VERSION "MFE26 real-VC / CarMaker RBS contract"

NS_ :

BS_:

BU_: VC SpeedgoatHIL CarMaker

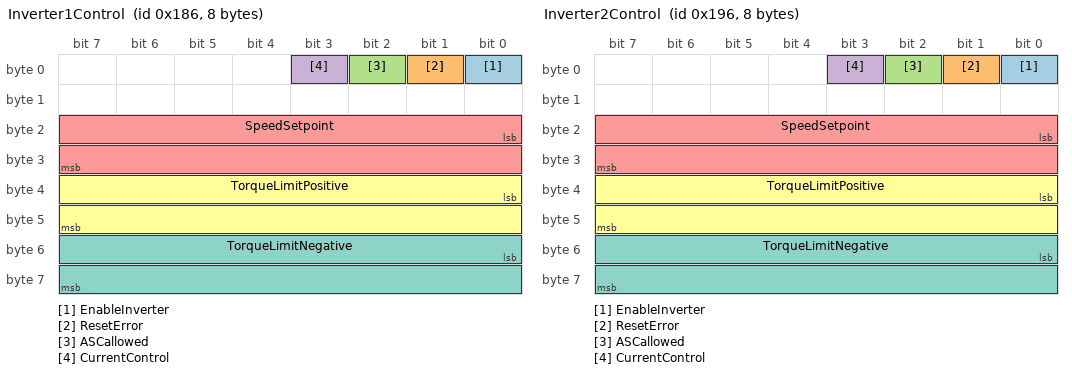
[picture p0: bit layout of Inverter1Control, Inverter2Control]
BO_ 390 Inverter1Control: 8 VC
 SG_ EnableInverter : 0|1@1+ (1,0) [0|1] "" SpeedgoatHIL,CarMaker
 SG_ ResetError : 1|1@1+ (1,0) [0|1] "" SpeedgoatHIL,CarMaker
 SG_ ASCallowed : 2|1@1+ (1,0) [0|1] "" SpeedgoatHIL,CarMaker
 SG_ CurrentControl : 3|1@1+ (1,0) [0|1] "" SpeedgoatHIL,CarMaker
 SG_ SpeedSetpoint : 16|16@1- (1,0) [-32768|32767] "RPM" SpeedgoatHIL,CarMaker
 SG_ TorqueLimitPositive : 32|16@1- (0.00390625,0) [-128|127.99609375] "Nm" SpeedgoatHIL,CarMaker
 SG_ TorqueLimitNegative : 48|16@1- (0.00390625,0) [-128|127.99609375] "Nm" SpeedgoatHIL,CarMaker
BO_ 406 Inverter2Control: 8 VC
 SG_ EnableInverter : 0|1@1+ (1,0) [0|1] "" SpeedgoatHIL,CarMaker
 SG_ ResetError : 1|1@1+ (1,0) [0|1] "" SpeedgoatHIL,CarMaker
 SG_ ASCallowed : 2|1@1+ (1,0) [0|1] "" SpeedgoatHIL,CarMaker
 SG_ CurrentControl : 3|1@1+ (1,0) [0|1] "" SpeedgoatHIL,CarMaker
 SG_ SpeedSetpoint : 16|16@1- (1,0) [-32768|32767] "RPM" SpeedgoatHIL,CarMaker
 SG_ TorqueLimitPositive : 32|16@1- (0.00390625,0) [-128|127.99609375] "Nm" SpeedgoatHIL,CarMaker
 SG_ TorqueLimitNegative : 48|16@1- (0.00390625,0) [-128|127.99609375] "Nm" SpeedgoatHIL,CarMaker
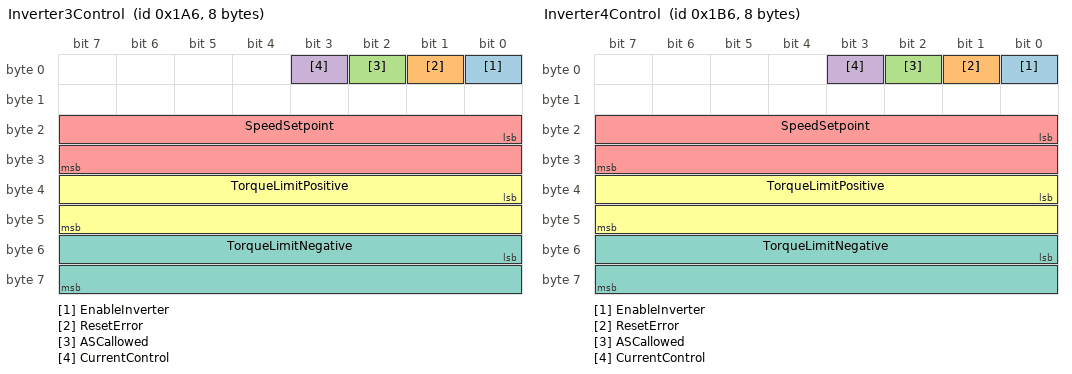
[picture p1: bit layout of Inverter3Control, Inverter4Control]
BO_ 422 Inverter3Control: 8 VC
 SG_ EnableInverter : 0|1@1+ (1,0) [0|1] "" SpeedgoatHIL,CarMaker
 SG_ ResetError : 1|1@1+ (1,0) [0|1] "" SpeedgoatHIL,CarMaker
 SG_ ASCallowed : 2|1@1+ (1,0) [0|1] "" SpeedgoatHIL,CarMaker
 SG_ CurrentControl : 3|1@1+ (1,0) [0|1] "" SpeedgoatHIL,CarMaker
 SG_ SpeedSetpoint : 16|16@1- (1,0) [-32768|32767] "RPM" SpeedgoatHIL,CarMaker
 SG_ TorqueLimitPositive : 32|16@1- (0.00390625,0) [-128|127.99609375] "Nm" SpeedgoatHIL,CarMaker
 SG_ TorqueLimitNegative : 48|16@1- (0.00390625,0) [-128|127.99609375] "Nm" SpeedgoatHIL,CarMaker
BO_ 438 Inverter4Control: 8 VC
 SG_ EnableInverter : 0|1@1+ (1,0) [0|1] "" SpeedgoatHIL,CarMaker
 SG_ ResetError : 1|1@1+ (1,0) [0|1] "" SpeedgoatHIL,CarMaker
 SG_ ASCallowed : 2|1@1+ (1,0) [0|1] "" SpeedgoatHIL,CarMaker
 SG_ CurrentControl : 3|1@1+ (1,0) [0|1] "" SpeedgoatHIL,CarMaker
 SG_ SpeedSetpoint : 16|16@1- (1,0) [-32768|32767] "RPM" SpeedgoatHIL,CarMaker
 SG_ TorqueLimitPositive : 32|16@1- (0.00390625,0) [-128|127.99609375] "Nm" SpeedgoatHIL,CarMaker
 SG_ TorqueLimitNegative : 48|16@1- (0.00390625,0) [-128|127.99609375] "Nm" SpeedgoatHIL,CarMaker

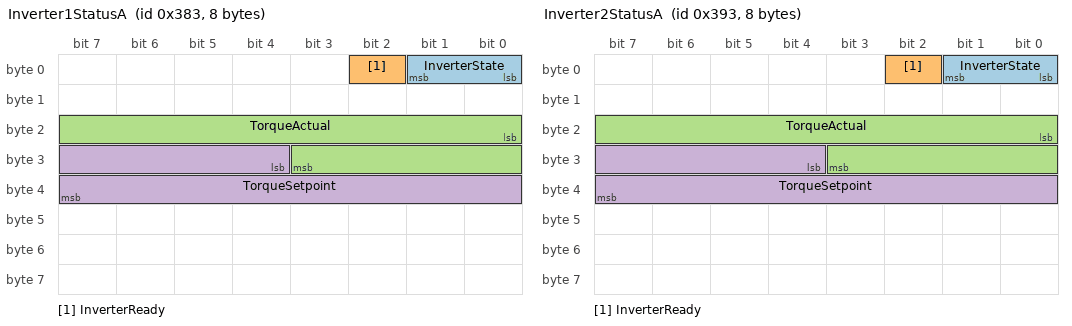
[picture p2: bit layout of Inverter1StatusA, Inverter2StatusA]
BO_ 899 Inverter1StatusA: 8 SpeedgoatHIL
 SG_ InverterState : 0|2@1+ (1,0) [0|3] "" VC,CarMaker
 SG_ InverterReady : 2|1@1+ (1,0) [0|1] "" VC,CarMaker
 SG_ TorqueActual : 16|12@1- (0.03125,0) [-64|63.96875] "Nm" VC,CarMaker
 SG_ TorqueSetpoint : 28|12@1- (0.03125,0) [-64|63.96875] "Nm" VC,CarMaker
BO_ 915 Inverter2StatusA: 8 SpeedgoatHIL
 SG_ InverterState : 0|2@1+ (1,0) [0|3] "" VC,CarMaker
 SG_ InverterReady : 2|1@1+ (1,0) [0|1] "" VC,CarMaker
 SG_ TorqueActual : 16|12@1- (0.03125,0) [-64|63.96875] "Nm" VC,CarMaker
 SG_ TorqueSetpoint : 28|12@1- (0.03125,0) [-64|63.96875] "Nm" VC,CarMaker
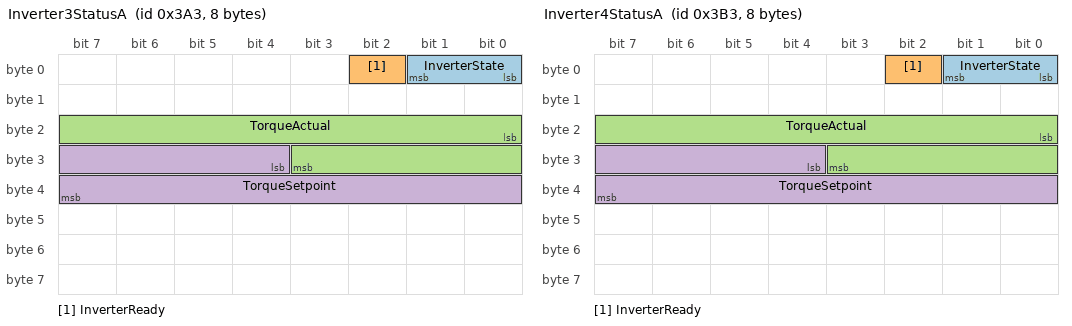
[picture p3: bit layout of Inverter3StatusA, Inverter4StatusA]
BO_ 931 Inverter3StatusA: 8 SpeedgoatHIL
 SG_ InverterState : 0|2@1+ (1,0) [0|3] "" VC,CarMaker
 SG_ InverterReady : 2|1@1+ (1,0) [0|1] "" VC,CarMaker
 SG_ TorqueActual : 16|12@1- (0.03125,0) [-64|63.96875] "Nm" VC,CarMaker
 SG_ TorqueSetpoint : 28|12@1- (0.03125,0) [-64|63.96875] "Nm" VC,CarMaker
BO_ 947 Inverter4StatusA: 8 SpeedgoatHIL
 SG_ InverterState : 0|2@1+ (1,0) [0|3] "" VC,CarMaker
 SG_ InverterReady : 2|1@1+ (1,0) [0|1] "" VC,CarMaker
 SG_ TorqueActual : 16|12@1- (0.03125,0) [-64|63.96875] "Nm" VC,CarMaker
 SG_ TorqueSetpoint : 28|12@1- (0.03125,0) [-64|63.96875] "Nm" VC,CarMaker

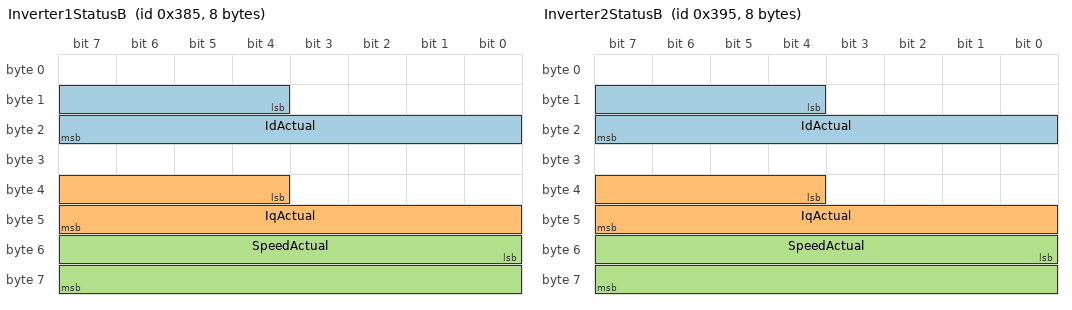
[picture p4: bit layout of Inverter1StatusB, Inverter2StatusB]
BO_ 901 Inverter1StatusB: 8 SpeedgoatHIL
 SG_ IdActual : 12|12@1- (0.0625,0) [-128|127.9375] "Arms" VC,CarMaker
 SG_ IqActual : 36|12@1- (0.0625,0) [-128|127.9375] "Arms" VC,CarMaker
 SG_ SpeedActual : 48|16@1- (1,0) [-32768|32767] "RPM" VC,CarMaker
BO_ 917 Inverter2StatusB: 8 SpeedgoatHIL
 SG_ IdActual : 12|12@1- (0.0625,0) [-128|127.9375] "Arms" VC,CarMaker
 SG_ IqActual : 36|12@1- (0.0625,0) [-128|127.9375] "Arms" VC,CarMaker
 SG_ SpeedActual : 48|16@1- (1,0) [-32768|32767] "RPM" VC,CarMaker
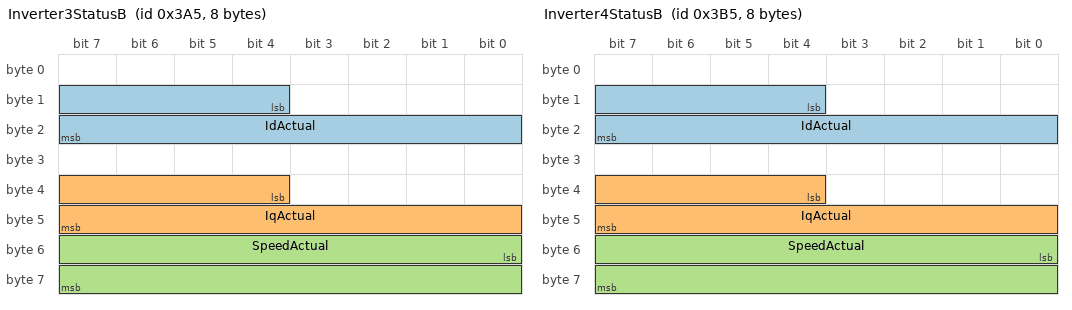
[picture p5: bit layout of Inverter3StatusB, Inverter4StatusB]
BO_ 933 Inverter3StatusB: 8 SpeedgoatHIL
 SG_ IdActual : 12|12@1- (0.0625,0) [-128|127.9375] "Arms" VC,CarMaker
 SG_ IqActual : 36|12@1- (0.0625,0) [-128|127.9375] "Arms" VC,CarMaker
 SG_ SpeedActual : 48|16@1- (1,0) [-32768|32767] "RPM" VC,CarMaker
BO_ 949 Inverter4StatusB: 8 SpeedgoatHIL
 SG_ IdActual : 12|12@1- (0.0625,0) [-128|127.9375] "Arms" VC,CarMaker
 SG_ IqActual : 36|12@1- (0.0625,0) [-128|127.9375] "Arms" VC,CarMaker
 SG_ SpeedActual : 48|16@1- (1,0) [-32768|32767] "RPM" VC,CarMaker
BO_ 1024 DCLinkStatus: 8 SpeedgoatHIL
 SG_ DCLinkVoltage12Actual : 0|16@1+ (0.015625,0) [0|1023.984375] "V" VC,CarMaker
 SG_ DCLinkVoltage34Actual : 16|16@1+ (0.015625,0) [0|1023.984375] "V" VC,CarMaker

BO_ 52 Sensor034: 8 VC
 SG_ RawPayload : 0|64@1+ (1,0) [0|1.8446744073709552e+19] "" SpeedgoatHIL,CarMaker
BO_ 50 Sensor032: 8 VC
 SG_ RawPayload : 0|64@1+ (1,0) [0|1.8446744073709552e+19] "" SpeedgoatHIL,CarMaker
BO_ 688 Sensor2B0: 8 VC
 SG_ RawPayload : 0|64@1+ (1,0) [0|1.8446744073709552e+19] "" SpeedgoatHIL,CarMaker

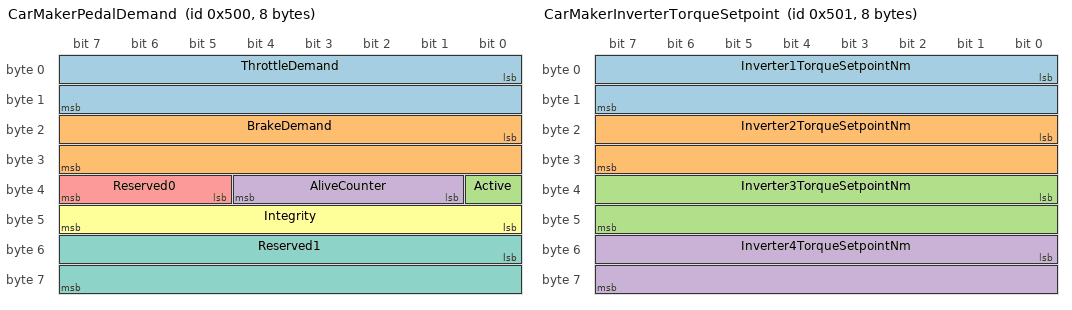
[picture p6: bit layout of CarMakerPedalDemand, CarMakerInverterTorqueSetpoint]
BO_ 1280 CarMakerPedalDemand: 8 CarMaker
 SG_ ThrottleDemand : 0|16@1+ (0.01,0) [0|100] "%" SpeedgoatHIL
 SG_ BrakeDemand : 16|16@1+ (0.01,0) [0|100] "%" SpeedgoatHIL
 SG_ Active : 32|1@1+ (1,0) [0|1] "" SpeedgoatHIL
 SG_ AliveCounter : 33|4@1+ (1,0) [0|15] "" SpeedgoatHIL
 SG_ Reserved0 : 37|3@1+ (1,0) [0|0] "" SpeedgoatHIL
 SG_ Integrity : 40|8@1+ (1,0) [0|255] "" SpeedgoatHIL
 SG_ Reserved1 : 48|16@1+ (1,0) [0|0] "" SpeedgoatHIL

BO_ 1281 CarMakerInverterTorqueSetpoint: 8 SpeedgoatHIL
 SG_ Inverter1TorqueSetpointNm : 0|16@1- (0.03125,0) [-1024|1023.96875] "Nm" CarMaker
 SG_ Inverter2TorqueSetpointNm : 16|16@1- (0.03125,0) [-1024|1023.96875] "Nm" CarMaker
 SG_ Inverter3TorqueSetpointNm : 32|16@1- (0.03125,0) [-1024|1023.96875] "Nm" CarMaker
 SG_ Inverter4TorqueSetpointNm : 48|16@1- (0.03125,0) [-1024|1023.96875] "Nm" CarMaker

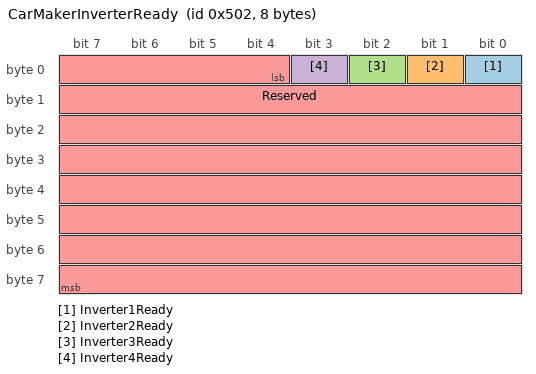
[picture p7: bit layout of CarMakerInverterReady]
BO_ 1282 CarMakerInverterReady: 8 SpeedgoatHIL
 SG_ Inverter1Ready : 0|1@1+ (1,0) [0|1] "" CarMaker
 SG_ Inverter2Ready : 1|1@1+ (1,0) [0|1] "" CarMaker
 SG_ Inverter3Ready : 2|1@1+ (1,0) [0|1] "" CarMaker
 SG_ Inverter4Ready : 3|1@1+ (1,0) [0|1] "" CarMaker
 SG_ Reserved : 4|60@1+ (1,0) [0|0] "" CarMaker

CM_ BO_ 1280 "Proposed design not built. Standard 11-bit ID 0x500, DLC 8, cyclic 10 ms, Intel/little-endian. Authoritative contract: inverter_hil/docs/can_pedal_demand_frame_spec.md on branch SG-CAN. Integrity is CRC-8/SAE-J1850 over bytes 1..5 in transmission order: width 8, poly 0x1D, init 0xFF, RefIn=false, RefOut=false, final XOR 0xFF; check value for five zero bytes is 0x10. Sender increments AliveCounter modulo 16 every emission, zeroes both reserved regions, and computes the CRC last. Receiver grants both pedal values CAN authority only when Active, alive-counter progression, integrity verification, range validation, and reserved-zero checks pass and age is under 100 ms; otherwise it atomically returns both pedals to the non-CAN source.";
CM_ BO_ 1281 "Standard 11-bit ID 0x501, DLC 8, cyclic 5 ms, Intel/little-endian. Authoritative contract: inverter_hil/docs/can_pedal_demand_frame_spec.md section 5 (CarMaker inverter telemetry wire contract), encoded by inverter_hil/+inverterhil/packCarMakerTelemetry.m, decoded on the CarMaker side by IO_In() in carmaker/FS_race/src_cm4sl/IO.c into the plain CarMaker Dictionary quantities MFE_CAN.TorqueRequestTotalNm (sum of the four channels) and consumed by TorqueVect.mdl's Read blocks. No application CRC or alive counter; sampled from and emitted alongside the same Ephorus status cycle as 0x502, but the two frames are not application-level atomic.";
CM_ BO_ 1282 "Standard 11-bit ID 0x502, DLC 8, cyclic 5 ms, Intel/little-endian. Companion to 0x501 -- see that message's comment. Decoded on the CarMaker side into MFE_CAN.DriveActive (four-way OR of the ready bits). All 60 reserved bits must be zero; a receiver rejects a nonzero reserved field.";
CM_ BO_ 52 "Confirmed ID only; signal layout is an open question and is retained as raw payload.";
CM_ BO_ 50 "Confirmed ID only; signal layout is an open question and is retained as raw payload.";
CM_ BO_ 688 "Confirmed ID only; signal layout is an open question and is retained as raw payload.";
BA_DEF_ BO_ "GenMsgCycleTime" INT 0 65535;
BA_ "GenMsgCycleTime" BO_ 1280 10;
BA_ "GenMsgCycleTime" BO_ 1281 5;
BA_ "GenMsgCycleTime" BO_ 1282 5;
